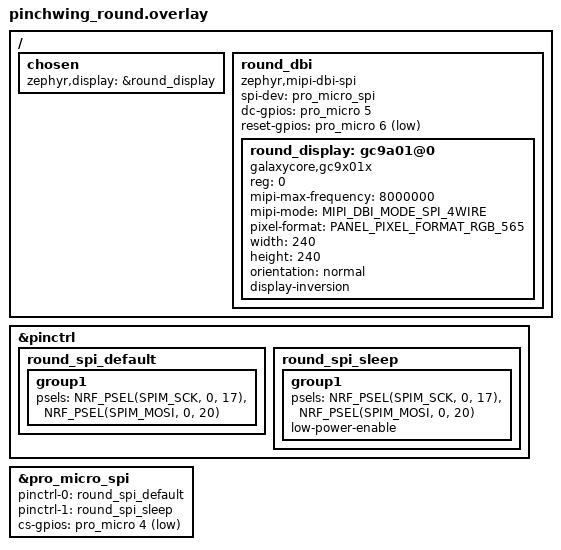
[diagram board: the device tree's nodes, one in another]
/* SPDX-License-Identifier: MIT */
#include <zephyr/dt-bindings/pinctrl/nrf-pinctrl.h>
#include <zephyr/dt-bindings/display/panel.h>

&pinctrl {
    round_spi_default: round_spi_default {
        group1 {
            psels = <NRF_PSEL(SPIM_SCK, 0, 17)>,
                    <NRF_PSEL(SPIM_MOSI, 0, 20)>;
        };
    };
    round_spi_sleep: round_spi_sleep {
        group1 {
            psels = <NRF_PSEL(SPIM_SCK, 0, 17)>,
                    <NRF_PSEL(SPIM_MOSI, 0, 20)>;
            low-power-enable;
        };
    };
};

&pro_micro_spi {
    status = "okay";
    pinctrl-0 = <&round_spi_default>;
    pinctrl-1 = <&round_spi_sleep>;
    pinctrl-names = "default", "sleep";
    cs-gpios = <&pro_micro 4 GPIO_ACTIVE_LOW>;
};

/ {
    chosen {
        zephyr,display = &round_display;
    };

    round_dbi {
        compatible = "zephyr,mipi-dbi-spi";
        spi-dev = <&pro_micro_spi>;
        dc-gpios = <&pro_micro 5 GPIO_ACTIVE_HIGH>;
        reset-gpios = <&pro_micro 6 GPIO_ACTIVE_LOW>;
        #address-cells = <1>;
        #size-cells = <0>;

        round_display: gc9a01@0 {
            compatible = "galaxycore,gc9x01x";
            reg = <0>;
            mipi-max-frequency = <8000000>;
            mipi-mode = "MIPI_DBI_MODE_SPI_4WIRE";
            pixel-format = <PANEL_PIXEL_FORMAT_RGB_565>;
            width = <240>;
            height = <240>;
            orientation = "normal";
            display-inversion;
        };
    };
};
